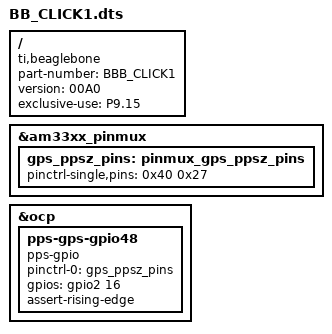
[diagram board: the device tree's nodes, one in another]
/*
 * mikroBUS Click cape, position 1
 * INT(PPS) on pin P9.15 (gpio48)
 */
/dts-v1/;
/plugin/;

/ {
	compatible = "ti,beaglebone", "ti,beaglebone-black", "ti,beaglebone-green";

        /* identification */
        part-number = "BBB_CLICK1";
        version = "00A0";

        /* state the resources this cape uses */
        exclusive-use =
                /* the pin header uses */
                "P9.15";        /* GPIO1_16/GPS PPS */

        fragment@0 {
                target = <&am33xx_pinmux>;
                __overlay__ {
                        gps_ppsz_pins: pinmux_gps_ppsz_pins {
				pinctrl-single,pins = <
				      0x40 0x27 /* P9.15 MODE7 GPIO1_16 */
				>;
			};
                };
        };

	fragment@1 {
		target = <&ocp>;
                __overlay__ {
                        pps-gps-gpio48 {
                                compatible = "pps-gpio";
                                status  = "okay";
                                pinctrl-names   = "default";
                                pinctrl-0       = <&gps_ppsz_pins>;
                                gpios   = <&gpio2 16 0>;  /* gpio2 == GPIO1 */
                                assert-rising-edge;
                        };
		};
	};
};
